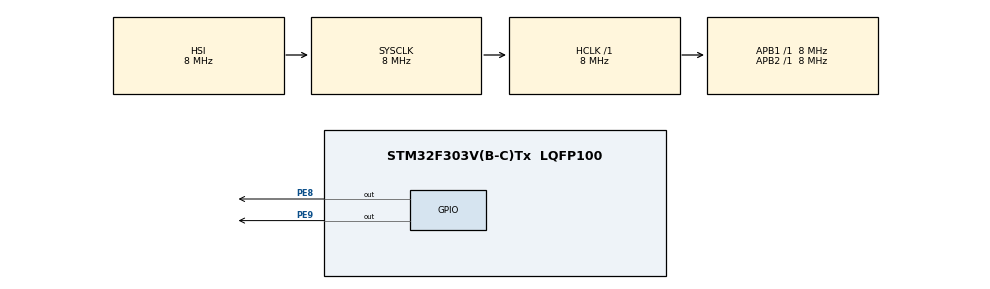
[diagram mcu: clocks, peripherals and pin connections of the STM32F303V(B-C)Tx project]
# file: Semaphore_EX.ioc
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FREERTOS.BinarySemaphores01=myBinarySem01,Dynamic,NULL,Available
FREERTOS.Tasks01=defaultTask,24,128,LED_TASK_1,Default,NULL,Dynamic,NULL,NULL;myTask02,8,128,LED_TASK_2,Default,NULL,Dynamic,NULL,NULL
FREERTOS.configUSE_NEWLIB_REENTRANT=1
Mcu.Family=STM32F3
Mcu.Name=STM32F303V(B-C)Tx
Mcu.Package=LQFP100
NVIC.PriorityGroup=NVIC_PRIORITYGROUP_4
PE8.Signal=GPIO_Output
PE9.Signal=GPIO_Output
ProjectManager.HeapSize=0x200
ProjectManager.StackSize=0x400
ProjectManager.TargetToolchain=STM32CubeIDE
RCC.AHBFreq_Value=8000000
RCC.APB1Freq_Value=8000000
RCC.APB2Freq_Value=8000000
RCC.CortexFreq_Value=8000000
RCC.HSE_VALUE=8000000
RCC.HSI_VALUE=8000000
RCC.LSE_VALUE=32768
RCC.SYSCLKFreq_VALUE=8000000
VP_FREERTOS_VS_CMSIS_V2.Mode=CMSIS_V2
board=custom

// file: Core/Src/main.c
/* USER CODE BEGIN Header */
/**
 ******************************************************************************
 * @file           : main.c
 * @brief          : Main program body
 ******************************************************************************
 * @attention
 *
 * Copyright (c) 2025 STMicroelectronics.
 * All rights reserved.
 *
 * This software is licensed under terms that can be found in the LICENSE file
 * in the root directory of this software component.
 * If no LICENSE file comes with this software, it is provided AS-IS.
 *
 ******************************************************************************
 */
/* USER CODE END Header */
#include "main.h"
#include "cmsis_os.h"

/* Definitions for defaultTask */
osThreadId_t defaultTaskHandle;
const osThreadAttr_t defaultTask_attributes = { .name = "defaultTask",
		.stack_size = 128 * 4, .priority = (osPriority_t) osPriorityNormal, };
/* Definitions for myTask02 */
osThreadId_t myTask02Handle;
const osThreadAttr_t myTask02_attributes = { .name = "myTask02", .stack_size =
		128 * 4, .priority = (osPriority_t) osPriorityNormal, };
/* Definitions for myBinarySem01 */
osSemaphoreId_t myBinarySem01Handle;
const osSemaphoreAttr_t myBinarySem01_attributes = { .name = "myBinarySem01" };

void SystemClock_Config(void);
static void MX_GPIO_Init(void);
void LED_TASK_1(void *argument);
void LED_TASK_2(void *argument);

int main(void) {

	/* MCU Configuration--------------------------------------------------------*/

	/* Reset of all peripherals, Initializes the Flash interface and the Systick. */
	HAL_Init();

	/* Configure the system clock */
	SystemClock_Config();

	/* Initialize all configured peripherals */
	MX_GPIO_Init();

	/* Init scheduler */
	osKernelInitialize();

	/* Create the semaphores(s) */
	/* creation of myBinarySem01 */
	myBinarySem01Handle = osSemaphoreNew(1, 1, &myBinarySem01_attributes);

	/* Create the thread(s) */
	/* creation of defaultTask */
	defaultTaskHandle = osThreadNew(LED_TASK_1, NULL, &defaultTask_attributes);

	/* creation of myTask02 */
	myTask02Handle = osThreadNew(LED_TASK_2, NULL, &myTask02_attributes);

	/* Start scheduler */
	osKernelStart();

	/* We should never get here as control is now taken by the scheduler */

	/* Infinite loop */
	while (1) {

	}
}

void SystemClock_Config(void) {
	RCC_OscInitTypeDef RCC_OscInitStruct = { 0 };
	RCC_ClkInitTypeDef RCC_ClkInitStruct = { 0 };

	/** Initializes the RCC Oscillators according to the specified parameters
	 * in the RCC_OscInitTypeDef structure.
	 */
	RCC_OscInitStruct.OscillatorType = RCC_OSCILLATORTYPE_HSI;
	RCC_OscInitStruct.HSIState = RCC_HSI_ON;
	RCC_OscInitStruct.HSICalibrationValue = RCC_HSICALIBRATION_DEFAULT;
	RCC_OscInitStruct.PLL.PLLState = RCC_PLL_NONE;
	if (HAL_RCC_OscConfig(&RCC_OscInitStruct) != HAL_OK) {
		Error_Handler();
	}

	/** Initializes the CPU, AHB and APB buses clocks
	 */
	RCC_ClkInitStruct.ClockType = RCC_CLOCKTYPE_HCLK | RCC_CLOCKTYPE_SYSCLK
			| RCC_CLOCKTYPE_PCLK1 | RCC_CLOCKTYPE_PCLK2;
	RCC_ClkInitStruct.SYSCLKSource = RCC_SYSCLKSOURCE_HSI;
	RCC_ClkInitStruct.AHBCLKDivider = RCC_SYSCLK_DIV1;
	RCC_ClkInitStruct.APB1CLKDivider = RCC_HCLK_DIV1;
	RCC_ClkInitStruct.APB2CLKDivider = RCC_HCLK_DIV1;

	if (HAL_RCC_ClockConfig(&RCC_ClkInitStruct, FLASH_LATENCY_0) != HAL_OK) {
		Error_Handler();
	}
}

static void MX_GPIO_Init(void) {
	GPIO_InitTypeDef GPIO_InitStruct = { 0 };

	/* GPIO Ports Clock Enable */
	__HAL_RCC_GPIOE_CLK_ENABLE();

	/*Configure GPIO pin Output Level */
	HAL_GPIO_WritePin(GPIOE, GPIO_PIN_8 | GPIO_PIN_9, GPIO_PIN_RESET);

	/*Configure GPIO pins : PE8 PE9 */
	GPIO_InitStruct.Pin = GPIO_PIN_8 | GPIO_PIN_9;
	GPIO_InitStruct.Mode = GPIO_MODE_OUTPUT_PP;
	GPIO_InitStruct.Pull = GPIO_NOPULL;
	GPIO_InitStruct.Speed = GPIO_SPEED_FREQ_LOW;
	HAL_GPIO_Init(GPIOE, &GPIO_InitStruct);

}

void LED_TASK_1(void *argument) {
	/* USER CODE BEGIN 5 */
	/* Infinite loop */
	for (;;) {
		// 세마포어 얻기 => osOk
		osSemaphoreAcquire(myBinarySem01Handle, osWaitForever);
		HAL_GPIO_TogglePin(GPIOE, GPIO_PIN_8);
		osDelay(500);
		//세마포어 반환하기
		osSemaphoreRelease(myBinarySem01Handle);
		osDelay(1); // 계속 task1이 점유하고 있어 잠깐 딜레이
		//configUSE_TIME_SLICING 1로 설정하면 라운드 로빈이 적용됨, CMSIS V2에서는 명시적으로 제시하지 않음
	}
	/* USER CODE END 5 */
}

void LED_TASK_2(void *argument) {
	/* USER CODE BEGIN LED_TASK_2 */
	/* Infinite loop */
	for (;;) {
		osSemaphoreAcquire(myBinarySem01Handle, osWaitForever);
		HAL_GPIO_TogglePin(GPIOE, GPIO_PIN_9);
		osDelay(500);
		osSemaphoreRelease(myBinarySem01Handle);
		osDelay(1);
	}
	/* USER CODE END LED_TASK_2 */
}

void Error_Handler(void) {
	__disable_irq();
	while (1) {
	}
}
